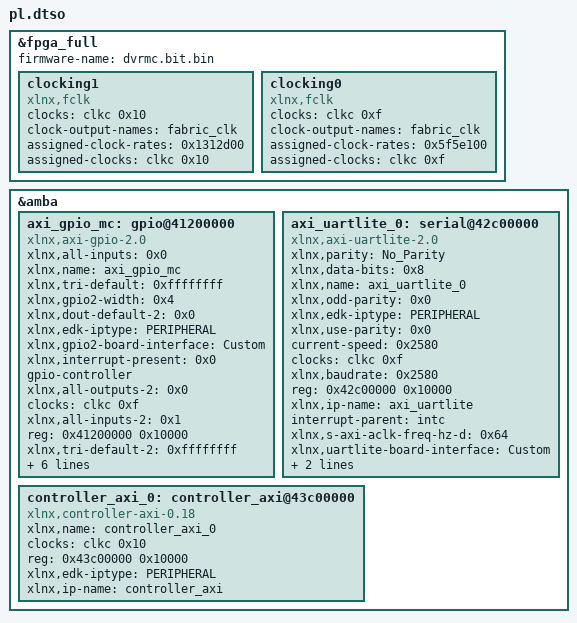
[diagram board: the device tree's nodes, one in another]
/dts-v1/;
/plugin/;

&fpga_full {
        firmware-name = "dvrmc.bit.bin";

        clocking1: clocking1 {
                clocks = <&clkc 0x10>;
                clock-output-names = "fabric_clk";
                #clock-cells = <0x0>;
                assigned-clock-rates = <0x1312d00>;
                assigned-clocks = <&clkc 0x10>;
                compatible = "xlnx,fclk";
        };

        clocking0: clocking0 {
                clocks = <&clkc 0xf>;
                clock-output-names = "fabric_clk";
                #clock-cells = <0x0>;
                assigned-clock-rates = <0x5f5e100>;
                assigned-clocks = <&clkc 0xf>;
                compatible = "xlnx,fclk";
        };
};

&amba {
        #address-cells = <1>;
        #size-cells = <1>;

        axi_gpio_mc: gpio@41200000 {
                xlnx,all-inputs = <0x0>;
                xlnx,name = "axi_gpio_mc";
                xlnx,tri-default = <0xffffffff>;
                clock-names = "s_axi_aclk";
                xlnx,gpio2-width = <0x4>;
                xlnx,dout-default-2 = <0x0>;
                xlnx,edk-iptype = "PERIPHERAL";
                xlnx,gpio2-board-interface = "Custom";
                xlnx,interrupt-present = <0x0>;
                device_type = "gpio";
                gpio-controller;
                xlnx,all-outputs-2 = <0x0>;
                clocks = <&clkc 0xf>;
                xlnx,all-inputs-2 = <0x1>;
                reg = <0x41200000 0x10000>;
                xlnx,tri-default-2 = <0xffffffff>;
                xlnx,ip-name = "axi_gpio";
                xlnx,is-dual = <0x1>;
                xlnx,dout-default = <0x0>;
                xlnx,gpio-width = <0x1>;
                #gpio-cells = <0x2>;
                xlnx,all-outputs = <0x1>;
                compatible = "xlnx,axi-gpio-2.0", "xlnx,xps-gpio-1.00.a";
                xlnx,gpio-board-interface = "Custom";
        };

        axi_uartlite_0: serial@42c00000 {
                xlnx,parity = "No_Parity";
                xlnx,data-bits = <0x8>;
                xlnx,name = "axi_uartlite_0";
                interrupt-names = "interrupt";
                clock-names = "s_axi_aclk";
                xlnx,odd-parity = <0x0>;
                xlnx,edk-iptype = "PERIPHERAL";
                xlnx,use-parity = <0x0>;
                device_type = "serial";
                current-speed = <0x2580>;
                clocks = <&clkc 0xf>;
                xlnx,baudrate = <0x2580>;
                reg = <0x42c00000 0x10000>;
                xlnx,ip-name = "axi_uartlite";
                interrupt-parent = <&intc>;
                xlnx,s-axi-aclk-freq-hz-d = <0x64>;
                xlnx,uartlite-board-interface = "Custom";
                port-number = <0x0>;
                compatible = "xlnx,axi-uartlite-2.0", "xlnx,xps-uartlite-1.00.a";
                interrupts = <0x0 0x1d 0x1>;
        };

        controller_axi_0: controller_axi@43c00000 {
                xlnx,name = "controller_axi_0";
                clocks = <&clkc 0x10>;
                reg = <0x43c00000 0x10000>;
                xlnx,edk-iptype = "PERIPHERAL";
                xlnx,ip-name = "controller_axi";
                clock-names = "clk";
                compatible = "xlnx,controller-axi-0.18";
        };
};

